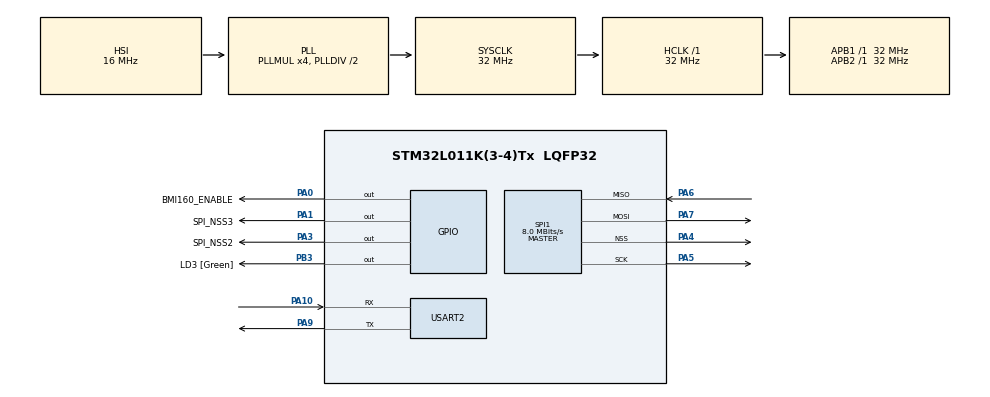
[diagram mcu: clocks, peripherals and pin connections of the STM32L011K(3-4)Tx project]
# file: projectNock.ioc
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Dma.Request0=SPI1_RX
Dma.Request1=SPI1_TX
Dma.SPI1_RX.0.Direction=DMA_PERIPH_TO_MEMORY
Dma.SPI1_RX.0.Instance=DMA1_Channel2
Dma.SPI1_RX.0.MemDataAlignment=DMA_MDATAALIGN_BYTE
Dma.SPI1_RX.0.MemInc=DMA_MINC_ENABLE
Dma.SPI1_RX.0.Mode=DMA_NORMAL
Dma.SPI1_RX.0.PeriphDataAlignment=DMA_PDATAALIGN_BYTE
Dma.SPI1_RX.0.PeriphInc=DMA_PINC_DISABLE
Dma.SPI1_RX.0.Priority=DMA_PRIORITY_LOW
Dma.SPI1_TX.1.Direction=DMA_MEMORY_TO_PERIPH
Dma.SPI1_TX.1.Instance=DMA1_Channel3
Dma.SPI1_TX.1.MemDataAlignment=DMA_MDATAALIGN_BYTE
Dma.SPI1_TX.1.MemInc=DMA_MINC_ENABLE
Dma.SPI1_TX.1.Mode=DMA_NORMAL
Dma.SPI1_TX.1.PeriphDataAlignment=DMA_PDATAALIGN_BYTE
Dma.SPI1_TX.1.PeriphInc=DMA_PINC_DISABLE
Dma.SPI1_TX.1.Priority=DMA_PRIORITY_LOW
Mcu.Family=STM32L0
Mcu.Name=STM32L011K(3-4)Tx
Mcu.Package=LQFP32
NVIC.DMA1_Channel2_3_IRQn=true\:0\:0\:false\:false\:true\:false
PA0-CK_IN.GPIO_Label=BMI160_ENABLE
PA0-CK_IN.Signal=GPIO_Output
PA1.GPIO_Label=SPI_NSS3
PA1.GPIO_Speed=GPIO_SPEED_FREQ_HIGH
PA1.PinState=GPIO_PIN_SET
PA1.Signal=GPIO_Output
PA10.Mode=Asynchronous
PA10.Signal=USART2_RX
PA13.GPIO_Label=TMS
PA13.Mode=Serial_Wire
PA13.Signal=SYS_SWDIO
PA14.GPIO_Label=TCK
PA14.Mode=Serial_Wire
PA14.Signal=SYS_SWCLK
PA3.GPIO_Label=SPI_NSS2
PA3.GPIO_Speed=GPIO_SPEED_FREQ_HIGH
PA3.PinState=GPIO_PIN_SET
PA3.Signal=GPIO_Output
PA4.Mode=NSS_Signal_Hard_Output
PA4.Signal=SPI1_NSS
PA5.Mode=Full_Duplex_Master
PA5.Signal=SPI1_SCK
PA6.Mode=Full_Duplex_Master
PA6.Signal=SPI1_MISO
PA7.Mode=Full_Duplex_Master
PA7.Signal=SPI1_MOSI
PA9.Mode=Asynchronous
PA9.Signal=USART2_TX
PB3.GPIO_Label=LD3 [Green]
PB3.GPIO_Speed=GPIO_SPEED_FREQ_HIGH
PB3.PinState=GPIO_PIN_SET
PB3.Signal=GPIO_Output
ProjectManager.HeapSize=0x100
ProjectManager.StackSize=0x100
ProjectManager.TargetToolchain=TrueSTUDIO
RCC.AHBFreq_Value=32000000
RCC.APB1Freq_Value=32000000
RCC.APB1TimFreq_Value=32000000
RCC.APB2Freq_Value=32000000
RCC.APB2TimFreq_Value=32000000
RCC.HCLKFreq_Value=32000000
RCC.HSE_VALUE=8000000
RCC.HSI16_VALUE=16000000
RCC.HSI48_VALUE=48000000
RCC.HSI_VALUE=16000000
RCC.LSE_VALUE=32768
RCC.MSI_VALUE=2097000
RCC.PLLMUL=RCC_PLLMUL_4
RCC.SYSCLKFreq_VALUE=32000000
RCC.SYSCLKSource=RCC_SYSCLKSOURCE_PLLCLK
RCC.VCOOutputFreq_Value=64000000
SPI1.BaudRatePrescaler=SPI_BAUDRATEPRESCALER_4
SPI1.CLKPhase=SPI_PHASE_1EDGE
SPI1.CLKPolarity=SPI_POLARITY_LOW
SPI1.CalculateBaudRate=8.0 MBits/s
SPI1.Direction=SPI_DIRECTION_2LINES
SPI1.Mode=SPI_MODE_MASTER
SPI1.VirtualNSS=VM_NSSHARD
SPI1.VirtualType=VM_MASTER
USART2.VirtualMode-Asynchronous=VM_ASYNC
board=NUCLEO-L011K4

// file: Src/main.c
/**
  ******************************************************************************
  * @file           : main.c
  * @brief          : Main program body
  ******************************************************************************
  ** This notice applies to any and all portions of this file
  * that are not between comment pairs USER CODE BEGIN and
  * USER CODE END. Other portions of this file, whether
  * inserted by the user or by software development tools
  * are owned by their respective copyright owners.
  *
  * COPYRIGHT(c) 2018 STMicroelectronics
  *
  * Redistribution and use in source and binary forms, with or without modification,
  * are permitted provided that the following conditions are met:
  *   1. Redistributions of source code must retain the above copyright notice,
  *      this list of conditions and the following disclaimer.
  *   2. Redistributions in binary form must reproduce the above copyright notice,
  *      this list of conditions and the following disclaimer in the documentation
  *      and/or other materials provided with the distribution.
  *   3. Neither the name of STMicroelectronics nor the names of its contributors
  *      may be used to endorse or promote products derived from this software
  *      without specific prior written permission.
  *
  * THIS SOFTWARE IS PROVIDED BY THE COPYRIGHT HOLDERS AND CONTRIBUTORS "AS IS"
  * AND ANY EXPRESS OR IMPLIED WARRANTIES, INCLUDING, BUT NOT LIMITED TO, THE
  * IMPLIED WARRANTIES OF MERCHANTABILITY AND FITNESS FOR A PARTICULAR PURPOSE ARE
  * DISCLAIMED. IN NO EVENT SHALL THE COPYRIGHT HOLDER OR CONTRIBUTORS BE LIABLE
  * FOR ANY DIRECT, INDIRECT, INCIDENTAL, SPECIAL, EXEMPLARY, OR CONSEQUENTIAL
  * DAMAGES (INCLUDING, BUT NOT LIMITED TO, PROCUREMENT OF SUBSTITUTE GOODS OR
  * SERVICES; LOSS OF USE, DATA, OR PROFITS; OR BUSINESS INTERRUPTION) HOWEVER
  * CAUSED AND ON ANY THEORY OF LIABILITY, WHETHER IN CONTRACT, STRICT LIABILITY,
  * OR TORT (INCLUDING NEGLIGENCE OR OTHERWISE) ARISING IN ANY WAY OUT OF THE USE
  * OF THIS SOFTWARE, EVEN IF ADVISED OF THE POSSIBILITY OF SUCH DAMAGE.
  *
  ******************************************************************************
  */
#include "main.h"
#include "stm32l0xx_hal.h"

/* USER CODE BEGIN Includes */
#include "bmi160.h"

/* USER CODE END Includes */

SPI_HandleTypeDef hspi1;
DMA_HandleTypeDef hdma_spi1_rx;
DMA_HandleTypeDef hdma_spi1_tx;

UART_HandleTypeDef huart2;

/* USER CODE BEGIN PV */
/* Private variables ---------------------------------------------------------*/

/* USER CODE END PV */

void SystemClock_Config(void);
static void MX_GPIO_Init(void);
static void MX_DMA_Init(void);
static void MX_SPI1_Init(void);
static void MX_USART2_UART_Init(void);

/* USER CODE BEGIN PFP */
/* Private function prototypes -----------------------------------------------*/

/* USER CODE END PFP */

int main(void)
{
  /* USER CODE BEGIN 1 */
	testTest();

  /* USER CODE END 1 */

  /* MCU Configuration----------------------------------------------------------*/

  /* Reset of all peripherals, Initializes the Flash interface and the Systick. */
  HAL_Init();

  /* Configure the system clock */
  SystemClock_Config();

  /* Initialize all configured peripherals */
  MX_GPIO_Init();
  MX_DMA_Init();
  MX_SPI1_Init();
  MX_USART2_UART_Init();
  /* USER CODE BEGIN 2 */
  BMI160_SPI_HARDWARE_DEF IMU = initBMI160(hspi1, SPI_NSS2_Pin, *GPIOA);
  initializeBMI160(IMU);

  /* USER CODE END 2 */

  /* Infinite loop */
  while (1)
  {

  /* USER CODE BEGIN 3 */

	  uint8_t data[3] = {0xff};
	  data[0] = regRead(IMU, 0x03);
	  data[1] = regRead(IMU, 0x0e);
	  HAL_UART_Transmit(&huart2, data, 3, 1000);

  }
  /* USER CODE END 3 */

}

void SystemClock_Config(void)
{

  RCC_OscInitTypeDef RCC_OscInitStruct;
  RCC_ClkInitTypeDef RCC_ClkInitStruct;
  RCC_PeriphCLKInitTypeDef PeriphClkInit;

    /**Configure the main internal regulator output voltage
    */
  __HAL_PWR_VOLTAGESCALING_CONFIG(PWR_REGULATOR_VOLTAGE_SCALE1);

    /**Initializes the CPU, AHB and APB busses clocks
    */
  RCC_OscInitStruct.OscillatorType = RCC_OSCILLATORTYPE_HSI;
  RCC_OscInitStruct.HSIState = RCC_HSI_ON;
  RCC_OscInitStruct.HSICalibrationValue = 16;
  RCC_OscInitStruct.PLL.PLLState = RCC_PLL_ON;
  RCC_OscInitStruct.PLL.PLLSource = RCC_PLLSOURCE_HSI;
  RCC_OscInitStruct.PLL.PLLMUL = RCC_PLLMUL_4;
  RCC_OscInitStruct.PLL.PLLDIV = RCC_PLLDIV_2;
  if (HAL_RCC_OscConfig(&RCC_OscInitStruct) != HAL_OK)
  {
    _Error_Handler(__FILE__, __LINE__);
  }

    /**Initializes the CPU, AHB and APB busses clocks
    */
  RCC_ClkInitStruct.ClockType = RCC_CLOCKTYPE_HCLK|RCC_CLOCKTYPE_SYSCLK
                              |RCC_CLOCKTYPE_PCLK1|RCC_CLOCKTYPE_PCLK2;
  RCC_ClkInitStruct.SYSCLKSource = RCC_SYSCLKSOURCE_PLLCLK;
  RCC_ClkInitStruct.AHBCLKDivider = RCC_SYSCLK_DIV1;
  RCC_ClkInitStruct.APB1CLKDivider = RCC_HCLK_DIV1;
  RCC_ClkInitStruct.APB2CLKDivider = RCC_HCLK_DIV1;

  if (HAL_RCC_ClockConfig(&RCC_ClkInitStruct, FLASH_LATENCY_1) != HAL_OK)
  {
    _Error_Handler(__FILE__, __LINE__);
  }

  PeriphClkInit.PeriphClockSelection = RCC_PERIPHCLK_USART2;
  PeriphClkInit.Usart2ClockSelection = RCC_USART2CLKSOURCE_PCLK1;
  if (HAL_RCCEx_PeriphCLKConfig(&PeriphClkInit) != HAL_OK)
  {
    _Error_Handler(__FILE__, __LINE__);
  }

    /**Configure the Systick interrupt time
    */
  HAL_SYSTICK_Config(HAL_RCC_GetHCLKFreq()/1000);

    /**Configure the Systick
    */
  HAL_SYSTICK_CLKSourceConfig(SYSTICK_CLKSOURCE_HCLK);

  /* SysTick_IRQn interrupt configuration */
  HAL_NVIC_SetPriority(SysTick_IRQn, 0, 0);
}

/* SPI1 init function */
static void MX_SPI1_Init(void)
{

  /* SPI1 parameter configuration*/
  hspi1.Instance = SPI1;
  hspi1.Init.Mode = SPI_MODE_MASTER;
  hspi1.Init.Direction = SPI_DIRECTION_2LINES;
  hspi1.Init.DataSize = SPI_DATASIZE_8BIT;
  hspi1.Init.CLKPolarity = SPI_POLARITY_LOW;
  hspi1.Init.CLKPhase = SPI_PHASE_1EDGE;
  hspi1.Init.NSS = SPI_NSS_HARD_OUTPUT;
  hspi1.Init.BaudRatePrescaler = SPI_BAUDRATEPRESCALER_4;
  hspi1.Init.FirstBit = SPI_FIRSTBIT_MSB;
  hspi1.Init.TIMode = SPI_TIMODE_DISABLE;
  hspi1.Init.CRCCalculation = SPI_CRCCALCULATION_DISABLE;
  hspi1.Init.CRCPolynomial = 7;
  if (HAL_SPI_Init(&hspi1) != HAL_OK)
  {
    _Error_Handler(__FILE__, __LINE__);
  }

}

/* USART2 init function */
static void MX_USART2_UART_Init(void)
{

  huart2.Instance = USART2;
  huart2.Init.BaudRate = 115200;
  huart2.Init.WordLength = UART_WORDLENGTH_8B;
  huart2.Init.StopBits = UART_STOPBITS_1;
  huart2.Init.Parity = UART_PARITY_NONE;
  huart2.Init.Mode = UART_MODE_TX_RX;
  huart2.Init.HwFlowCtl = UART_HWCONTROL_NONE;
  huart2.Init.OverSampling = UART_OVERSAMPLING_16;
  huart2.Init.OneBitSampling = UART_ONE_BIT_SAMPLE_DISABLE;
  huart2.AdvancedInit.AdvFeatureInit = UART_ADVFEATURE_NO_INIT;
  if (HAL_UART_Init(&huart2) != HAL_OK)
  {
    _Error_Handler(__FILE__, __LINE__);
  }

}

static void MX_DMA_Init(void)
{
  /* DMA controller clock enable */
  __HAL_RCC_DMA1_CLK_ENABLE();

  /* DMA interrupt init */
  /* DMA1_Channel2_3_IRQn interrupt configuration */
  HAL_NVIC_SetPriority(DMA1_Channel2_3_IRQn, 0, 0);
  HAL_NVIC_EnableIRQ(DMA1_Channel2_3_IRQn);

}

/** Configure pins as
        * Analog
        * Input
        * Output
        * EVENT_OUT
        * EXTI
*/
static void MX_GPIO_Init(void)
{

  GPIO_InitTypeDef GPIO_InitStruct;

  /* GPIO Ports Clock Enable */
  __HAL_RCC_GPIOA_CLK_ENABLE();
  __HAL_RCC_GPIOB_CLK_ENABLE();

  /*Configure GPIO pin Output Level */
  HAL_GPIO_WritePin(BMI160_ENABLE_GPIO_Port, BMI160_ENABLE_Pin, GPIO_PIN_RESET);

  /*Configure GPIO pin Output Level */
  HAL_GPIO_WritePin(GPIOA, SPI_NSS3_Pin|SPI_NSS2_Pin, GPIO_PIN_SET);

  /*Configure GPIO pin Output Level */
  HAL_GPIO_WritePin(LD3_GPIO_Port, LD3_Pin, GPIO_PIN_SET);

  /*Configure GPIO pin : BMI160_ENABLE_Pin */
  GPIO_InitStruct.Pin = BMI160_ENABLE_Pin;
  GPIO_InitStruct.Mode = GPIO_MODE_OUTPUT_PP;
  GPIO_InitStruct.Pull = GPIO_NOPULL;
  GPIO_InitStruct.Speed = GPIO_SPEED_FREQ_LOW;
  HAL_GPIO_Init(BMI160_ENABLE_GPIO_Port, &GPIO_InitStruct);

  /*Configure GPIO pins : SPI_NSS3_Pin SPI_NSS2_Pin */
  GPIO_InitStruct.Pin = SPI_NSS3_Pin|SPI_NSS2_Pin;
  GPIO_InitStruct.Mode = GPIO_MODE_OUTPUT_PP;
  GPIO_InitStruct.Pull = GPIO_NOPULL;
  GPIO_InitStruct.Speed = GPIO_SPEED_FREQ_HIGH;
  HAL_GPIO_Init(GPIOA, &GPIO_InitStruct);

  /*Configure GPIO pin : LD3_Pin */
  GPIO_InitStruct.Pin = LD3_Pin;
  GPIO_InitStruct.Mode = GPIO_MODE_OUTPUT_PP;
  GPIO_InitStruct.Pull = GPIO_NOPULL;
  GPIO_InitStruct.Speed = GPIO_SPEED_FREQ_HIGH;
  HAL_GPIO_Init(LD3_GPIO_Port, &GPIO_InitStruct);

}

void _Error_Handler(char *file, int line)
{
  while(1)
  {
  }
}

/************************ (C) COPYRIGHT STMicroelectronics *****END OF FILE****/
